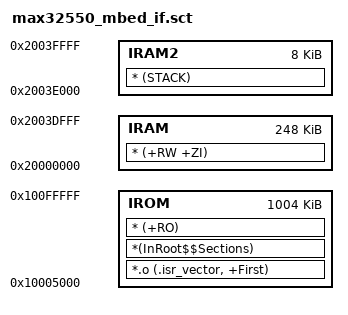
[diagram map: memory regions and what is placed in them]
; *************************************************************
; **** Scatter-Loading Description File for Maxim MAX32550 ****
; *************************************************************

LR 0x10005000 0x000FB000  {    ; load region size_region
  IROM 0x10005000 0x000FB000  {  ; load address = execution address
    *.o (.isr_vector, +First)
    *(InRoot$$Sections)
    * (+RO)
  }
  IRAM 0x20000000 0x0003E000  {  ; RW data
    * (+RW +ZI)
  }
  IRAM2 0x2003E000 0x00002000  {
    * (STACK)
  }
}
